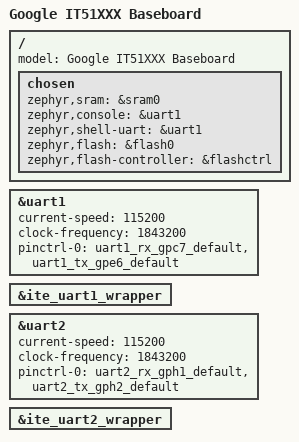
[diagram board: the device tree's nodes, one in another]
/* Copyright 2025 The ChromiumOS Authors
 * Use of this source code is governed by a BSD-style license that can be
 * found in the LICENSE file.
 */

#include <cros/ite/it51xxx.dtsi>
#include <dt-bindings/gpio_defines.h>
#include <dt-bindings/gpio/ite-it8xxx2-gpio.h>
#include <ite/it51xxx-pinctrl-map.dtsi>

#define GPIO_VOLTAGE_1P8 IT8XXX2_GPIO_VOLTAGE_1P8

/ {
	model = "Google IT51XXX Baseboard";

	chosen {
		zephyr,sram = &sram0;
		zephyr,console = &uart1;
		zephyr,shell-uart = &uart1;
		zephyr,flash = &flash0;
		zephyr,flash-controller = &flashctrl;
	};
};

&uart1 {
	status = "okay";
	current-speed = <115200>;
	clock-frequency = <1843200>;
	pinctrl-0 = <&uart1_rx_gpc7_default
		     &uart1_tx_gpe6_default>;
	pinctrl-names = "default";
};

&ite_uart1_wrapper {
	status = "okay";

};

&uart2 {
	status = "okay";
	current-speed = <115200>;
	clock-frequency = <1843200>;
	pinctrl-0 = <&uart2_rx_gph1_default
		     &uart2_tx_gph2_default>;
	pinctrl-names = "default";
};

&ite_uart2_wrapper {
	status = "okay";

};
